VERSION "created by canmatrix"

NS_ :

BS_:

BU_: NODE1

BO_ 1365 msg6: 8 Vector__XXX
 SG_ msg6_sig1 : 0|64@1+ (1,0) [0|1.84467440737096E+019] "" Vector__XXX

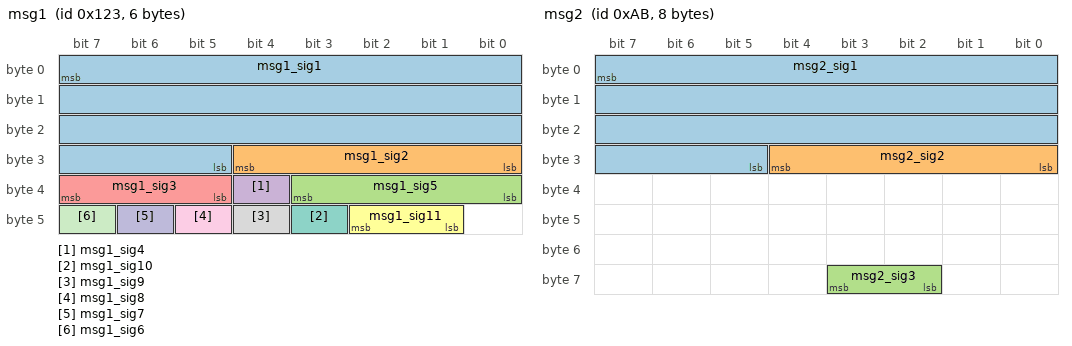
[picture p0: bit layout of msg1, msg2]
BO_ 291 msg1: 6 Vector__XXX
 SG_ msg1_sig1 : 7|27@0+ (1,0) [0|134217727] ""  NODE1
 SG_ msg1_sig2 : 28|5@0+ (1,0) [0|31] ""  NODE1
 SG_ msg1_sig5 : 35|4@0+ (1,0) [0|15] ""  NODE1
 SG_ msg1_sig4 : 36|1@0+ (1,0) [0|1] ""  NODE1
 SG_ msg1_sig3 : 39|3@0+ (1,0) [0|1] ""  NODE1
 SG_ msg1_sig11 : 42|2@0+ (1,0) [0|3] ""  NODE1
 SG_ msg1_sig10 : 43|1@0+ (1,0) [0|1] ""  NODE1
 SG_ msg1_sig9 : 44|1@0+ (1,0) [0|1] ""  NODE1
 SG_ msg1_sig8 : 45|1@0+ (1,0) [0|1] ""  NODE1
 SG_ msg1_sig7 : 46|1@0+ (1,0) [0|1] ""  NODE1
 SG_ msg1_sig6 : 47|1@0+ (1,0) [0|1] ""  NODE1

BO_ 1110 msg3: 8 Vector__XXX
 SG_ msg3_sig1 : 23|16@0+ (0.0015259,-50) [-50|49.9998565] "%"  NODE1

BO_ 171 msg2: 8 NODE1
 SG_ msg2_sig1 : 7|27@0+ (1,0) [0|134217727] "" Vector__XXX
 SG_ msg2_sig2 : 28|5@0+ (1,0) [0|31] "" Vector__XXX
 SG_ msg2_sig3 : 59|2@0+ (1,0) [0|3] "" Vector__XXX

BO_ 2452903544 msg4: 8 Vector__XXX

BO_ 2452903545 msg5: 8 NODE1

BA_DEF_ BO_  "GenMsgCycleTime" INT 0 65535;
BA_DEF_ BO_  "GenMsgDelayTime" INT 0 65535;
BA_DEF_ BO_  "GenMsgNrOfRepetitions" INT 0 65535;
BA_DEF_ BO_  "GenMsgSendType" ENUM  "cyclicX","spontanX","cyclicIfActiveX","spontanWithDelay","cyclicAndSpontanX","cyclicAndSpontanWithDelay","spontanWithRepitition","cyclicIfActiveAndSpontanWD","cyclicIfActiveFast","cyclicWithRepeatOnDemand","none";
BA_DEF_ BO_  "GenMsgStartValue" STRING ;
BA_DEF_ SG_  "GenSigStartValue" HEX 0 4294967295;
BA_DEF_ BU_  "NWM-Knoten" ENUM  "nein","ja";
BA_DEF_ BU_  "NWM-Stationsadresse" HEX 0 63;
BA_DEF_DEF_  "GenMsgCycleTime" 0;
BA_DEF_DEF_  "GenMsgDelayTime" 0;
BA_DEF_DEF_  "GenMsgNrOfRepetitions" 0;
BA_DEF_DEF_  "GenMsgSendType" "";
BA_DEF_DEF_  "GenMsgStartValue" "";
BA_DEF_DEF_  "GenSigStartValue" 0;
BA_DEF_DEF_  "NWM-Knoten" "";
BA_DEF_DEF_  "NWM-Stationsadresse" 0;
BA_ "NWM-Knoten" BU_ NODE1 0;
BA_ "GenMsgCycleTime" BO_ 291 250;
BA_ "GenMsgDelayTime" BO_ 291 25;
BA_ "GenMsgSendType" BO_ 291 5;
BA_ "GenMsgStartValue" BO_ 291 "000000000000";
BA_ "GenMsgSendType" BO_ 1110 1;
BA_ "GenMsgStartValue" BO_ 1110 "0000000000000000";
BA_ "GenMsgCycleTime" BO_ 171 50;
BA_ "GenMsgSendType" BO_ 171 0;
BA_ "GenMsgStartValue" BO_ 171 "0000000000000000";
BA_ "GenMsgSendType" BO_ 2452903544 1;
BA_ "GenMsgStartValue" BO_ 2452903544 "0000000000000000";
BA_ "GenMsgSendType" BO_ 2452903545 1;
BA_ "GenMsgStartValue" BO_ 2452903545 "0000000000000000";
BA_ "GenSigStartValue" SG_ 1110 msg3_sig1 32767.5470214301;
VAL_ 291 msg1_sig4 0 "FALSE" 1 "TRUE" ;
VAL_ 291 msg1_sig3 0 "Off" 1 "Accessory" 2 "Run" 3 "Start Request" 4 "Propulsion" ;
VAL_ 291 msg1_sig10 0 "FALSE" 1 "TRUE" ;
VAL_ 291 msg1_sig9 0 "FALSE" 1 "TRUE" ;
VAL_ 291 msg1_sig8 0 "FALSE" 1 "TRUE" ;
VAL_ 291 msg1_sig7 0 "FALSE" 1 "TRUE" ;
VAL_ 291 msg1_sig6 0 "FALSE" 1 "TRUE" ;
SIG_GROUP_ 291 msg1_group 1 : msg1_sig11 msg1_sig3 msg1_sig4 msg1_sig2 msg1_sig1 msg1_sig5 msg1_sig6 msg1_sig7 msg1_sig8 msg1_sig9 msg1_sig10;
SIG_GROUP_ 171 msg2_group 1 : msg2_sig3 msg2_sig2 msg2_sig1;
